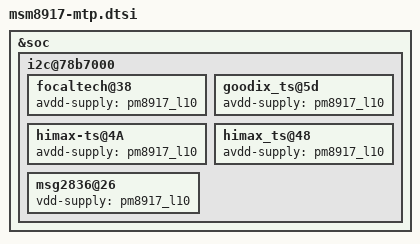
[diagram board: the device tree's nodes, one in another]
/*
 * Copyright (c) 2015-2018, The Linux Foundation. All rights reserved.
 *
 * This program is free software; you can redistribute it and/or modify
 * it under the terms of the GNU General Public License version 2 and
 * only version 2 as published by the Free Software Foundation.
 *
 * This program is distributed in the hope that it will be useful,
 * but WITHOUT ANY WARRANTY; without even the implied warranty of
 * MERCHANTABILITY or FITNESS FOR A PARTICULAR PURPOSE.  See the
 * GNU General Public License for more details.
 */

&soc {
	i2c@78b7000 {
		focaltech@38 {
			avdd-supply = <&pm8917_l10>;
		};

		goodix_ts@5d {
			avdd-supply = <&pm8917_l10>;
		};

		himax-ts@4A {
			avdd-supply = <&pm8917_l10>;
		};

		himax_ts@48 {
			avdd-supply = <&pm8917_l10>;
		};

		msg2836@26 {
			vdd-supply = <&pm8917_l10>;
		};
	};
};
